# STM32H725xx register map
File version: 1.0
Registers are 32-bit, read-write, reset 0x0 unless marked. A register's access mark holds for its fields unless they carry their own. Offsets are from the block's base; [hi:lo] are bit positions.

## COMP1
Base 0x5800380C
Same registers: COMP2 0x58003810
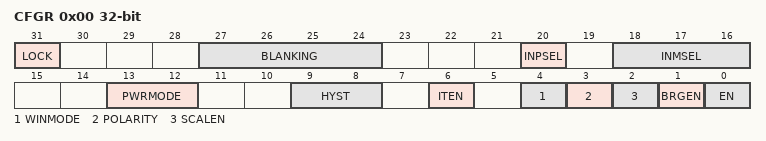
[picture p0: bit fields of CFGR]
0x00 CFGR — Comparator configuration register
  [31] LOCK — COMPx Lock Bit
  [27:24] BLANKING — COMPx blanking source selection bits
    0=NONE (Comparator output without blanking); 1=TIM1_OC5 (Comparator output blanking source TIM1 OC5 (common to all COMP instances: COMP1, COMP2)); 2=TIM2_OC3 (Comparator output blanking source TIM2 OC3 (common to all COMP instances: COMP1, COMP2)); 3=TIM3_OC3 (Comparator output blanking source TIM3 OC3 (common to all COMP instances: COMP1, COMP2)); 4=TIM3_OC4 (Comparator output blanking source TIM3 OC4 (common to all COMP instances: COMP1, COMP2)); 5=TIM8_OC5 (Comparator output blanking source TIM8 OC5 (common to all COMP instances: COMP1, COMP2)); 6=TIM15_OC1 (Comparator output blanking source TIM15 OC1 (common to all COMP instances: COMP1, COMP2))
  [20] INPSEL — COMPx input plus selection bit
  [18:16] INMSEL — COMPx input minus selection bit
  [13:12] PWRMODE — COMPx Power Mode of the comparator
    0=HIGHSPEED (COMP power mode to high speed); 1=MEDIUMSPEED (COMP power mode to medium speed); 3=ULTRALOWPOWER (COMP power mode to ultra-low power)
  [9:8] HYST — COMPx hysteresis selection bits
    0=NONE (No hysteresis); 1=LOW (Hysteresis level low); 2=MEDIUM (Hysteresis level medium); 3=HIGH (Hysteresis level high)
  [6] ITEN — COMPx interrupt enable
  [4] WINMODE — COMPx Windows mode selection bit
    0=DISABLE (Window mode disable: Comparators 1 and 2 are independent); 1=COMP1_INPUT_PLUS_COMMON (Window mode enable: Comparators instances pair COMP1 and COMP2 have their input plus connected together. The common input is COMP1 input plus (COMP2 input plus is no more accessible).)
  [3] POLARITY — COMPx polarity selection bit
    0=NONINVERTED (COMP output polarity is not inverted: comparator output is high when the plus (non-inverting) input is at a higher voltage than the minus (inverting) input); 1=INVERTED (COMP output polarity is inverted: comparator output is low when the plus (non-inverting) input is at a lower voltage than the minus (inverting) input)
  [2] SCALEN — COMPx Voltage scaler enable bit
  [1] BRGEN — COMPx Scaler bridge enable
  [0] EN — COMPx enable bit

## VREFBUF
Base 0x58003C00
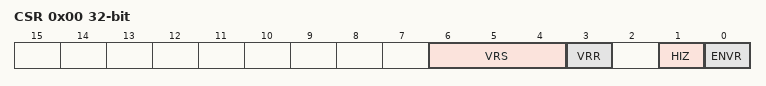
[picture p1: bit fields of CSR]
0x00 CSR — VREFBUF control and status register
  [6:4] VRS — Voltage reference scale
  [3] VRR — Voltage reference buffer ready
  [1] HIZ — High impedance mode
  [0] ENVR — Voltage reference buffer enable
0x04 CCR — VREFBUF calibration and control register
  [5:0] TRIM — TRIM[5:0] bits (Trimming code)

## IWDG1 — Independent WATCHDOG
Base 0x58004800
0x00 KR — IWDG Key register
  [15:0] KEY — Key value (write only, read 0000h)
0x04 PR — IWDG Prescaler register
  [2:0] PR — PR[2:0] (Prescaler divider)
0x08 RLR — IWDG Reload register
  [11:0] RL — Watchdog counter reload value
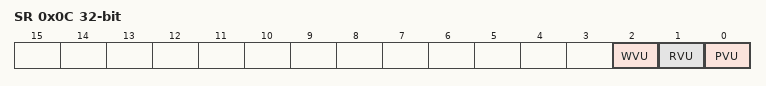
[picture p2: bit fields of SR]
0x0C SR — IWDG Status register
  [2] WVU — Watchdog counter window value update
  [1] RVU — Watchdog counter reload value update
  [0] PVU — Watchdog prescaler value update
0x10 WINR — IWDG Window register
  [11:0] WIN — Watchdog counter window value

## DTS
Base 0x58006800
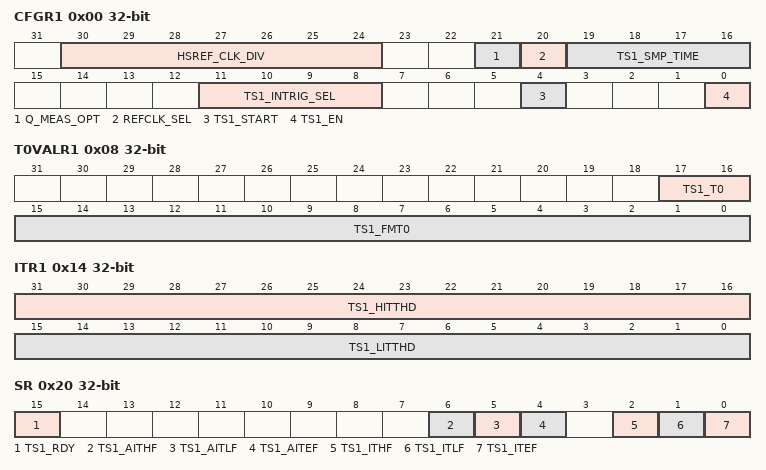
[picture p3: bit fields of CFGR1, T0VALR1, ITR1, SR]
0x00 CFGR1 — DTS configuration register
  [30:24] HSREF_CLK_DIV — High Speed Clock Divider Ratio [6:0]
  [21] Q_MEAS_OPT — Quick measure option bit
  [20] REFCLK_SEL — Reference Clock Selection
  [19:16] TS1_SMP_TIME — Sample time [3:0] for DTS
  [11:8] TS1_INTRIG_SEL — Input triggers selection bits [3:0] for DTS
  [4] TS1_START — Proceed to a frequency measurement on DTS
  [0] TS1_EN — DTS Enable
0x08 T0VALR1 — DTS T0 Value register
  [17:16] TS1_T0 — Engineering value of the DTSerature T0 for DTS
  [15:0] TS1_FMT0 — Engineering value of the measured frequency at T0 for DTS
0x10 RAMPVALR — DTS Ramp value register
  [15:0] TS1_RAMP_COEFF — Engineering value of the ramp coefficient for DTS
0x14 ITR1 — DTS Interrupt threshold register
  [31:16] TS1_HITTHD — High interrupt threshold[15:0] for DTS
  [15:0] TS1_LITTHD — Low interrupt threshold[15:0] for DTS
0x1C DR — DTS data register
  [15:0] TS1_MFREQ — Measured Frequency[15:0] for DTS
0x20 SR — DTS status register
  [15] TS1_RDY — DTS ready flag
  [6] TS1_AITHF — Asynchronous interrupt flag for high threshold for DTS
  [5] TS1_AITLF — Asynchronous interrupt flag for low threshold for DTS
  [4] TS1_AITEF — Asynchronous interrupt flag for end of measure for DTS
  [2] TS1_ITHF — Interrupt flag for high threshold for DTS
  [1] TS1_ITLF — Interrupt flag for low threshold for DTS
  [0] TS1_ITEF — Interrupt flag for end of measure for DTS
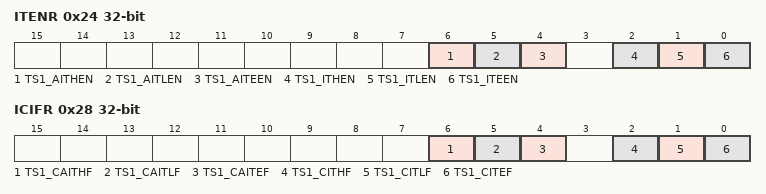
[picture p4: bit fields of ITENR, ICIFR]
0x24 ITENR — DTS Interrupt enable register
  [6] TS1_AITHEN — Enable asynchronous interrupt flag for high threshold for DTS
  [5] TS1_AITLEN — Enable Asynchronous interrupt flag for low threshold for DTS
  [4] TS1_AITEEN — Enable asynchronous interrupt flag for end of measure for DTS
  [2] TS1_ITHEN — Enable interrupt flag for high threshold for DTS
  [1] TS1_ITLEN — Enable interrupt flag for low threshold for DTS
  [0] TS1_ITEEN — Enable interrupt flag for end of measure for DTS
0x28 ICIFR — DTS Clear Interrupt flag register
  [6] TS1_CAITHF — Clear the asynchronous IT flag for high threshold on DTS
  [5] TS1_CAITLF — Clear the asynchronous IT flag for low threshold for DTS
  [4] TS1_CAITEF — Clear the asynchronous IT flag for End Of Measure for DTS
  [2] TS1_CITHF — Clear the IT flag for high threshold on DTS
  [1] TS1_CITLF — Clear the IT flag for low threshold for DTS
  [0] TS1_CITEF — Clear the IT flag for End Of Measure for DTS
0x2C OR — DTS option register 1
